# PWMSS_EQEP register map
Vendor: Texas Instruments
Peripheral module from a debugger description file (folder am437x).
Registers are 16-bit, read-write, no defined reset value unless marked. A register's access mark holds for its fields unless they carry their own. Offsets are as the file gives them; lines under a group give offsets from that group; [hi:lo] are bit positions; {n}, {i} and the like mark numbered series; 'fields as' and 'values as' point back to an identical list; <NAME> marks a mode.

## PWMSS_EQEP
0x00 QPOSCNT 32-bit
  [31:0] QPOSCNT — This 32 bit position counter register counts up/down on every eQEP pulse based on direction input. [[br]]This counter acts as a position integrator whose count value is proportional to position from a give reference point. [[br]]
0x04 QPOSINIT 32-bit
  [31:0] QPOSINIT — This register contains the position value that is used to initialize the position counter based on external strobe or index event. [[br]]The position counter can be initialized through software.
0x08 QPOSMAX 32-bit
  [31:0] QPOSMAX — This register contains the maximum position counter value.
0x0C QPOSCMP 32-bit
  [31:0] QPOSCMP — The position-compare value in this register is compared with the position counter (QPOSCNT) to generate sync output and/or interrupt on compare match.
0x10 QPOSILAT 32-bit ro
  [31:0] QPOSILAT — The position-counter value is latched into this register on an index event as defined by the QEPCTL[IEL] bits.
0x14 QPOSSLAT 32-bit ro
  [31:0] QPOSSLAT — The position-counter value is latched into this register on strobe event as defined by the QEPCTL[SEL] bits.
0x18 QPOSLAT 32-bit ro
  [31:0] QPOSLAT — The position-counter value is latched into this register on unit time out event.
0x1C QUTMR 32-bit
  [31:0] QUTMR — This register acts as time base for unit time event generation. [[br]]When this timer value matches with unit time period value, unit time event is generated.
0x20 QUPRD 32-bit
  [31:0] QUPRD — This register contains the period count for unit timer to generate periodic unit time events to latch the eQEP position information at periodic interval and optionally to generate interrupt.
0x24 QWDTMR
  [15:0] QWDTMR — This register acts as time base for watch dog to detect motor stalls. [[br]]When this timer value matches with watch dog period value, watch dog timeout interrupt is generated. [[br]]This register is reset upon edge transition in quadrature-clock indicating the motion.
0x26 QWDPRD
  [15:0] QWDPRD — This register contains the time-out count for the eQEP peripheral watch dog timer. [[br]]When the watchdog timer value matches the watchdog period value, a watchdog timeout interrupt is generated.
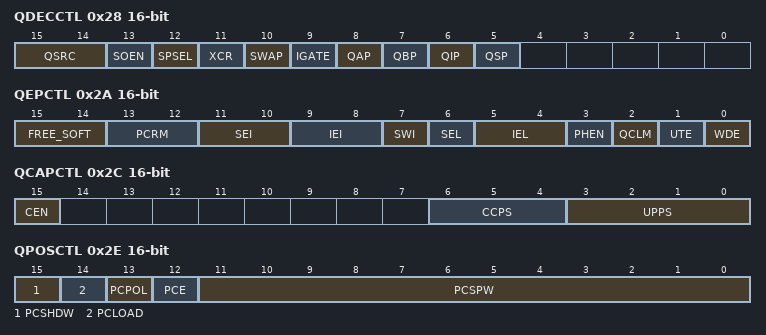
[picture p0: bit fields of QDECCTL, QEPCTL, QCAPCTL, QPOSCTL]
0x28 QDECCTL access per field
  [15:14] QSRC rw — Position-counter source selection.
    3=en_4_0x3 (DOWN count mode for frequency measurement (QCLK = xCLK, QDIR = 0)); 2=en_3_0x2 (UP count mode for frequency measurement (QCLK = xCLK, QDIR = 1)); 1=en_2_0x1 (Direction-count mode (QCLK = xCLK, QDIR = xDIR)); 0=en_1_0x0 (Quadrature count mode (QCLK = iCLK, QDIR = iDIR))
  [13] SOEN rw — Sync output-enable
    1=en_2_0x1 (Enable position-compare sync output); 0=en_1_0x0 (Disable position-compare sync output)
  [12] SPSEL rw — Sync output pin selection
    1=en_2_0x1 (Strobe pin is used for sync output); 0=en_1_0x0 (Index pin is used for sync output)
  [11] XCR rw — External clock rate
    1=en_2_0x1 (1x resolution: Count the rising edge only); 0=en_1_0x0 (2x resolution: Count the rising/falling edge)
  [10] SWAP rw — Swap quadrature clock inputs. [[br]]This swaps the input to the quadrature decoder, reversing the counting direction.
    1=en_2_0x1 (Quadrature-clock inputs are swapped); 0=en_1_0x0 (Quadrature-clock inputs are not swapped)
  [9] IGATE rw — Index pulse gating option
    1=en_2_0x1 (Gate the index pin with strobe); 0=en_1_0x0 (Disable gating of Index pulse)
  [8] QAP rw — QEPA input polarity
    1=en_2_0x1 (Negates QEPA input); 0=en_1_0x0 (No effect)
  [7] QBP rw — QEPB input polarity
    1=en_2_0x1 (Negates QEPB input); 0=en_1_0x0 (No effect)
  [6] QIP rw — QEPI input polarity
    1=en_2_0x1 (Negates QEPI input); 0=en_1_0x0 (No effect)
  [5] QSP rw — QEPS input polarity
    1=en_2_0x1 (Negates QEPS input); 0=en_1_0x0 (No effect)
0x2A QEPCTL
  [15:14] FREE_SOFT — Emulation Control Bits. [[br]]In the values 0 through 3 listed below, x is different for the four following behaviors. [[br]]QPOSCNT behavior, x refers to the Position counter. [[br]]QWDTMR behavior, x refers to the Watchdog counter. [[br]]QUTMR behavior, x refers to the Unit timer. [[br]]QCTMR behavior, x refers to the Capture timer.
    3=en_4_0x3 (x is unaffected by emulation suspend.); 2=en_3_0x2 (x is unaffected by emulation suspend.); 1=en_2_0x1 (x continues to count until the rollover.); 0=en_1_0x0 (x stops immediately. For QPOSCNT behavior, the stop is on emulation suspend.)
  [13:12] PCRM — Position counter reset mode
    3=en_4_0x3 (Position counter reset on a unit time event); 2=en_3_0x2 (Position counter reset on the first index event); 1=en_2_0x1 (Position counter reset on the maximum position); 0=en_1_0x0 (Position counter reset on an index event)
  [11:10] SEI — Strobe event initialization of position counter
    3=en_4_0x3 (Clockwise Direction: Initializes the position counter on the rising edge of QEPS strobe. Counter Clockwise Direction: Initializes the position counter on the falling edge of QEPS strobe); 2=en_3_0x2 (Initializes the position counter on rising edge of the QEPS signal); 1=en_2_0x1 (Does nothing (action disabled)); 0=en_1_0x0 (Does nothing (action disabled))
  [9:8] IEI — Index event initialization of position counter
    3=en_4_0x3 (Initializes the position counter on the falling edge of QEPI signal (QPOSCNT = QPOSINIT)); 2=en_3_0x2 (Initializes the position counter on the rising edge of the QEPI signal (QPOSCNT = QPOSINIT)); 1=en_2_0x1 (Do nothing (action disabled)); 0=en_1_0x0 (Do nothing (action disabled))
  [7] SWI — Software initialization of position counter
    1=en_2_0x1 (Initialize position counter, this bit is cleared automatically); 0=en_1_0x0 (Do nothing (action disabled))
  [6] SEL — Strobe event latch of position counter
    1=en_2_0x1 (Clockwise Direction: Position counter is latched on rising edge of QEPS strobe. Counter Clockwise Direction: Position counter is latched on falling edge of QEPS strobe.); 0=en_1_0x0 (The position counter is latched on the rising edge of QEPS strobe (QPOSSLAT = POSCCNT). Latching on the falling edge can be done by inverting the strobe input using the QSP bit in the QDECCTL register.)
  [5:4] IEL — Index event latch of position counter (software index marker)
    3=en_4_0x3 (Software index marker. Latches the position counter and quadrature direction flag on index event marker. The position counter is latched to the QPOSILAT register and the direction flag is latched in the QEPSTS[QDLF] bit. This mode is useful for software index marking.); 2=en_3_0x2 (Latches position counter on falling edge of the index signal); 1=en_2_0x1 (Latches position counter on rising edge of the index signal); 0=en_1_0x0 (Reserved)
  [3] PHEN — Quadrature position counter enable/software reset
    1=en_2_0x1 (eQEP position counter is enabled); 0=en_1_0x0 (Reset the eQEP peripheral internal operating flags/read-only registers. Control/configuration registers are not disturbed by a software reset.)
  [2] QCLM — eQEP capture latch mode
    1=en_2_0x1 (Latch on unit time out. Position counter, capture timer and capture period values are latched into QPOSLAT, QCTMRLAT and QCPRDLAT registers on unit time out.); 0=en_1_0x0 (Latch on position counter read by CPU. Capture timer and capture period values are latched into QCTMRLAT and QCPRDLAT registers when CPU reads the QPOSCNT register.)
  [1] UTE — eQEP unit timer enable
    1=en_2_0x1 (Enable unit timer); 0=en_1_0x0 (Disable eQEP unit timer)
  [0] WDE — eQEP watchdog enable
    1=en_2_0x1 (Enable the eQEP watchdog timer); 0=en_1_0x0 (Disable the eQEP watchdog timer)
0x2C QCAPCTL access per field
  [15] CEN rw — Enable eQEP capture
    1=en_2_0x1 (eQEP capture unit is enabled); 0=en_1_0x0 (eQEP capture unit is disabled)
  [6:4] CCPS rw — eQEP capture timer clock prescaler
    7=en_8_0x7 (CAPCLK = SYSCLKOUT/128); 6=en_7_0x6 (CAPCLK = SYSCLKOUT/64); 5=en_6_0x5 (CAPCLK = SYSCLKOUT/32); 4=en_5_0x4 (CAPCLK = SYSCLKOUT/16); 3=en_4_0x3 (CAPCLK = SYSCLKOUT/8); 2=en_3_0x2 (CAPCLK = SYSCLKOUT/4); 1=en_2_0x1 (CAPCLK = SYSCLKOUT/2); 0=en_1_0x0 (CAPCLK = SYSCLKOUT/1)
  [3:0] UPPS rw — Unit position event prescaler
    {v}=en_{v+1}_{0x0+v} (Reserved) (v=12..15); 11=en_12_0xB (UPEVNT = QCLK/2048); 10=en_11_0xA (UPEVNT = QCLK/1024); 9=en_10_0x9 (UPEVNT = QCLK/512); 8=en_9_0x8 (UPEVNT = QCLK/256); 7=en_8_0x7 (UPEVNT = QCLK/128); 6=en_7_0x6 (UPEVNT = QCLK/64); 5=en_6_0x5 (UPEVNT = QCLK/32); 4=en_5_0x4 (UPEVNT = QCLK/16); 3=en_4_0x3 (UPEVNT = QCLK/8); 2=en_3_0x2 (UPEVNT = QCLK/4); 1=en_2_0x1 (UPEVNT = QCLK/2); 0=en_1_0x0 (UPEVNT = QCLK/1)
0x2E QPOSCTL
  [15] PCSHDW — Position-compare shadow enable
    1=en_2_0x1 (Shadow enabled); 0=en_1_0x0 (Shadow disabled, load Immediate)
  [14] PCLOAD — Position-compare shadow load mode
    1=en_2_0x1 (Load when QPOSCNT = QPOSCMP); 0=en_1_0x0 (Load on QPOSCNT = 0)
  [13] PCPOL — Polarity of sync output
    1=en_2_0x1 (Active LOW pulse output); 0=en_1_0x0 (Active HIGH pulse output)
  [12] PCE — Position-compare enable/disable
    1=en_2_0x1 (Enable position compare unit); 0=en_1_0x0 (Disable position compare unit)
  [11:0] PCSPW — Select-position-compare sync output pulse width ...
    0xFFF=en_4_0xFFF (3 x 4 x SYSCLKOUT cycles to 4096 x 4 x SYSCLKOUT cycles); 2=en_3_0x2 (3 x 4 x SYSCLKOUT cycles to 4096 x 4 x SYSCLKOUT cycles); 1=en_2_0x1 (2 x 4 x SYSCLKOUT cycles); 0=en_1_0x0 (1 x 4 x SYSCLKOUT cycles)
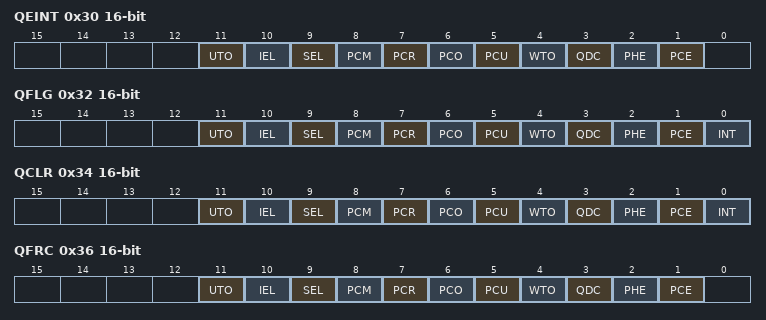
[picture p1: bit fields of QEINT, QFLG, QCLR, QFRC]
0x30 QEINT access per field
  [all] fields
    1=en_2_0x1 (Interrupt is enabled); 0=en_1_0x0 (Interrupt is disabled)
  [11] UTO rw — Unit time out interrupt enable
  [10] IEL rw — Index event latch interrupt enable
  [9] SEL rw — Strobe event latch interrupt enable
  [8] PCM rw — Position-compare match interrupt enable
  [7] PCR rw — Position-compare ready interrupt enable
  [6] PCO rw — Position counter overflow interrupt enable
  [5] PCU rw — Position counter underflow interrupt enable
  [4] WTO rw — Watchdog time out interrupt enable
  [3] QDC rw — Quadrature direction change interrupt enable
  [2] PHE rw — Quadrature phase error interrupt enable
  [1] PCE rw — Position counter error interrupt enable
0x32 QFLG ro
  [11] UTO — Unit time out interrupt flag
    1=en_2_0x1 (Set by eQEP unit timer period match); 0=en_1_0x0 (No interrupt generated)
  [10] IEL — Index event latch interrupt flag
    1=en_2_0x1 (This bit is set after latching the QPOSCNT to QPOSILAT); 0=en_1_0x0 (No interrupt generated)
  [9] SEL — Strobe event latch interrupt flag
    1=en_2_0x1 (This bit is set after latching the QPOSCNT to QPOSSLAT); 0=en_1_0x0 (No interrupt generated)
  [8] PCM — eQEP compare match event interrupt flag
    1=en_2_0x1 (This bit is set on position-compare match); 0=en_1_0x0 (No interrupt generated)
  [7] PCR — Position-compare ready interrupt flag
    1=en_2_0x1 (This bit is set after transferring the shadow register value to the active position compare register.); 0=en_1_0x0 (No interrupt generated)
  [6] PCO — Position counter overflow interrupt flag
    1=en_2_0x1 (This bit is set on position counter overflow.); 0=en_1_0x0 (No interrupt generated)
  [5] PCU — Position counter underflow interrupt flag
    1=en_2_0x1 (This bit is set on position counter underflow.); 0=en_1_0x0 (No interrupt generated)
  [4] WTO — Watchdog timeout interrupt flag
    1=en_2_0x1 (Set by watch dog timeout); 0=en_1_0x0 (No interrupt generated)
  [3] QDC — Quadrature direction change interrupt flag
    1=en_2_0x1 (This bit is set during change of direction); 0=en_1_0x0 (No interrupt generated)
  [2] PHE — Quadrature phase error interrupt flag
    1=en_2_0x1 (Set on simultaneous transition of QEPA and QEPB); 0=en_1_0x0 (No interrupt generated)
  [1] PCE — Position counter error interrupt flag
    1=en_2_0x1 (Position counter error); 0=en_1_0x0 (No interrupt generated)
  [0] INT — Global interrupt status flag
    1=en_2_0x1 (Interrupt was generated); 0=en_1_0x0 (No interrupt generated)
0x34 QCLR access per field
  [11] UTO rw — Clear unit time out interrupt flag
    1=en_2_0x1 (Clears the interrupt flag); 0=en_1_0x0 (No effect)
  [10] IEL rw — Clear index event latch interrupt flag
    values as UTO
  [9] SEL rw — Clear strobe event latch interrupt flag
    values as UTO
  [8] PCM rw — Clear eQEP compare match event interrupt flag
    values as UTO
  [7] PCR rw — Clear position-compare ready interrupt flag
    values as UTO
  [6] PCO rw — Clear position counter overflow interrupt flag
    values as UTO
  [5] PCU rw — Clear position counter underflow interrupt flag
    values as UTO
  [4] WTO rw — Clear watchdog timeout interrupt flag
    values as UTO
  [3] QDC rw — Clear quadrature direction change interrupt flag
    values as UTO
  [2] PHE rw — Clear quadrature phase error interrupt flag
    values as UTO
  [1] PCE rw — Clear position counter error interrupt flag
    values as UTO
  [0] INT rw — Global interrupt clear flag
    1=en_2_0x1 (Clears the interrupt flag and enables further interrupts to be generated if an event flags is set to 1.); 0=en_1_0x0 (No effect)
0x36 QFRC access per field
  [all] fields
    1=en_2_0x1 (Force the interrupt); 0=en_1_0x0 (No effect)
  [11] UTO rw — Force unit time out interrupt
  [10] IEL rw — Force index event latch interrupt
  [9] SEL rw — Force strobe event latch interrupt
  [8] PCM rw — Force position-compare match interrupt
  [7] PCR rw — Force position-compare ready interrupt
  [6] PCO rw — Force position counter overflow interrupt
  [5] PCU rw — Force position counter underflow interrupt
  [4] WTO rw — Force watchdog time out interrupt
  [3] QDC rw — Force quadrature direction change interrupt
  [2] PHE rw — Force quadrature phase error interrupt
  [1] PCE rw — Force position counter error interrupt
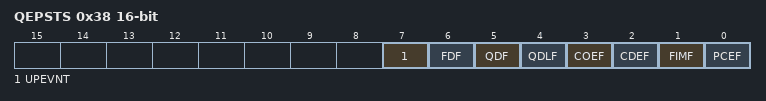
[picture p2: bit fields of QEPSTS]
0x38 QEPSTS access per field
  [7] UPEVNT ro — Unit position event flag
    1=en_2_0x1 (Unit position event detected. Write 1 to clear.); 0=en_1_0x0 (No unit position event detected)
  [6] FDF ro — Direction on the first index marker. [[br]]Status of the direction is latched on the first index event marker.
    1=en_2_0x1 (Clockwise rotation (or forward movement) on the first index event); 0=en_1_0x0 (Counter-clockwise rotation (or reverse movement) on the first index event)
  [5] QDF ro — Quadrature direction flag
    1=en_2_0x1 (Clockwise rotation (or forward movement)); 0=en_1_0x0 (Counter-clockwise rotation (or reverse movement))
  [4] QDLF ro — eQEP direction latch flag. [[br]]Status of direction is latched on every index event marker.
    1=en_2_0x1 (Clockwise rotation (or forward movement) on index event marker); 0=en_1_0x0 (Counter-clockwise rotation (or reverse movement) on index event marker)
  [3] COEF rw — Capture overflow error flag
    1=en_2_0x1 (Overflow occurred in eQEP Capture timer (QEPCTMR)); 0=en_1_0x0 (Sticky bit, cleared by writing 1)
  [2] CDEF rw — Capture direction error flag
    1=en_2_0x1 (Direction change occurred between the capture position event.); 0=en_1_0x0 (Sticky bit, cleared by writing 1)
  [1] FIMF rw — First index marker flag
    1=en_2_0x1 (Set by first occurrence of index pulse); 0=en_1_0x0 (Sticky bit, cleared by writing 1)
  [0] PCEF ro — Position counter error flag. [[br]]This bit is not sticky and it is updated for every index event.
    1=en_2_0x1 (Position counter error); 0=en_1_0x0 (No error occurred during the last index transition.)
0x3A QCTMR
  [15:0] QCTMR — This register provides time base for edge capture unit.
0x3C QCPRD
  [15:0] QCPRD — This register holds the period count value between the last successive eQEP position events
0x3E QCTMRLAT ro
  [15:0] QCTMRLAT — The eQEP capture timer value can be latched into this register on two events, that is, unit timeout event, reading the eQEP position counter.
0x40 QCPRDLAT
  [15:0] QCPRDLAT — eQEP capture period value can be latched into this register on two events, that is, unit timeout event, reading the eQEP position counter.
0x5C REVID 32-bit ro
  [31:0] REV — eQEP revision ID
